# HT32F125x register map
File version: 1.1
CPU: CM3 r2p0, little endian, no MPU, no FPU, 4 interrupt priority bits
Registers are 32-bit, read-write, reset 0x0 unless marked. A register's access mark holds for its fields unless they carry their own. Offsets are from the block's base; [hi:lo] are bit positions; {n}, {i} and the like mark numbered series.

## FMC
Base 0x40080000
0x00 FMC_TADR
  [31:0] TADB
0x04 FMC_WRDR
  [31:0] WRDB
0x0C FMC_OCMR
  [3:0] CMD
0x10 FMC_OPCR
  [4:1] OPM
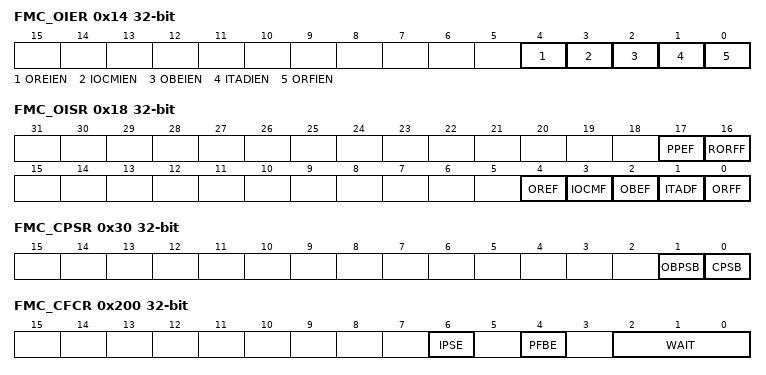
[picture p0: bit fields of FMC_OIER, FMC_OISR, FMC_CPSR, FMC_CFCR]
0x14 FMC_OIER
  [4] OREIEN, [3] IOCMIEN, [2] OBEIEN, [1] ITADIEN, [0] ORFIEN
0x18 FMC_OISR
  [17] PPEF, [16] RORFF, [4] OREF, [3] IOCMF, [2] OBEF, [1] ITADF, [0] ORFF
{0x20+4i} FMC_PPSR{i} (i=0..3)
  [31:0] PPSB
0x30 FMC_CPSR
  [1] OBPSB, [0] CPSB
0x100 FMC_VMCR
  [1:0] VMCB
0x200 FMC_CFCR
  [6] IPSE, [4] PFBE, [2:0] WAIT
{0x300+4i} FMC_SBVT{i} (i=0..3)
  [31:0] SBVT

## PWRCU
Base 0x4006A100
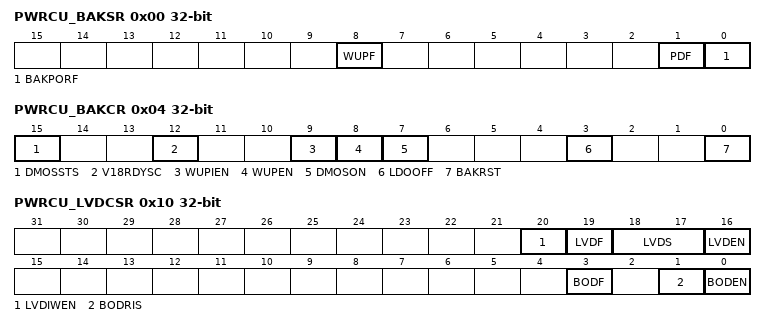
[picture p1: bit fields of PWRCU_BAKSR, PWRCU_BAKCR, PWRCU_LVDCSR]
0x00 PWRCU_BAKSR
  [8] WUPF, [1] PDF, [0] BAKPORF
0x04 PWRCU_BAKCR
  [15] DMOSSTS, [12] V18RDYSC, [9] WUPIEN, [8] WUPEN, [7] DMOSON, [3] LDOOFF, [0] BAKRST
0x08 PWRCU_BAKTEST
  [7:0] BAKTEST
0x0C PWRCU_HSIRCR
  [1:0] HSIRCBL
0x10 PWRCU_LVDCSR
  [20] LVDIWEN, [19] LVDF, [18:17] LVDS, [16] LVDEN, [3] BODF, [1] BODRIS, [0] BODEN
{0x100+4i} PWRCU_BAKREG{i} (i=0..9)
  [31:0] BAKREG

## CKCU
Base 0x40088000
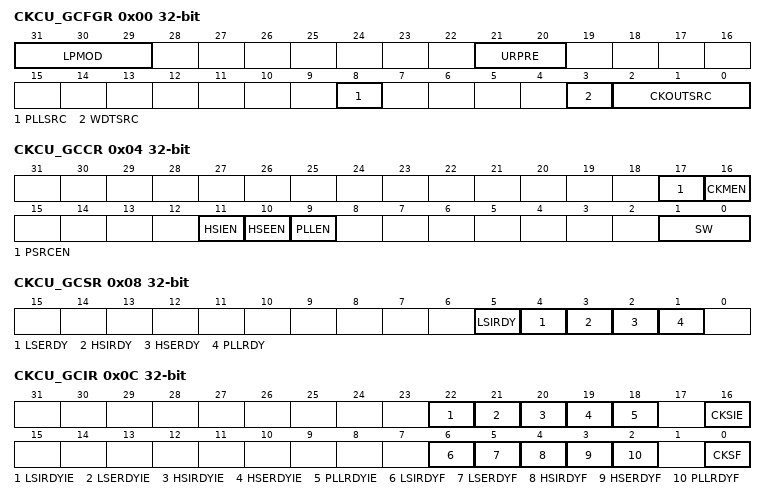
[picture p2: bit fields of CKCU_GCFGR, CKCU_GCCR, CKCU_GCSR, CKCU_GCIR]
0x00 CKCU_GCFGR
  [31:29] LPMOD, [21:20] URPRE, [8] PLLSRC, [3] WDTSRC, [2:0] CKOUTSRC
0x04 CKCU_GCCR
  [17] PSRCEN, [16] CKMEN, [11] HSIEN, [10] HSEEN, [9] PLLEN, [1:0] SW
0x08 CKCU_GCSR
  [5] LSIRDY, [4] LSERDY, [3] HSIRDY, [2] HSERDY, [1] PLLRDY
0x0C CKCU_GCIR
  [22] LSIRDYIE, [21] LSERDYIE, [20] HSIRDYIE, [19] HSERDYIE, [18] PLLRDYIE, [16] CKSIE, [6] LSIRDYF, [5] LSERDYF, [4] HSIRDYF, [3] HSERDYF, [2] PLLRDYF, [0] CKSF
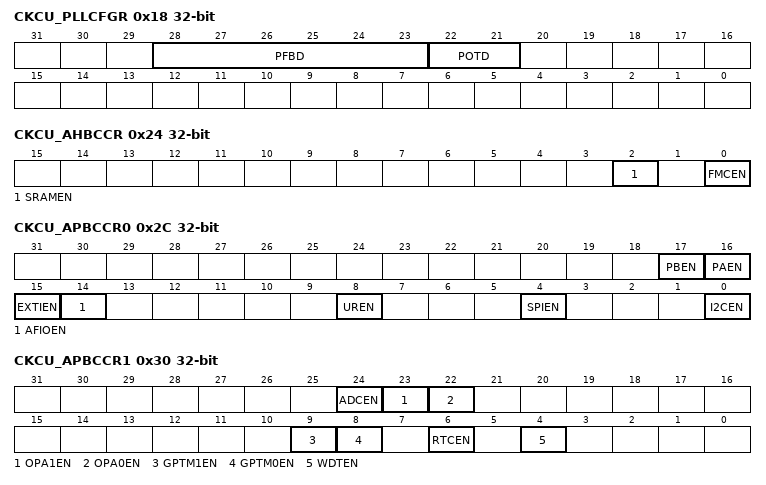
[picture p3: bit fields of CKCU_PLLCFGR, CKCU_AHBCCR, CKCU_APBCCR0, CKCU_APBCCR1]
0x18 CKCU_PLLCFGR
  [28:23] PFBD, [22:21] POTD
0x1C CKCU_PLLCR
  [31] PLLBPS
0x20 CKCU_AHBCFGR
  [1:0] AHBPRE
0x24 CKCU_AHBCCR
  [2] SRAMEN, [0] FMCEN
0x28 CKCU_APBCFGR
  [18:16] ADCDIV
0x2C CKCU_APBCCR0
  [17] PBEN, [16] PAEN, [15] EXTIEN, [14] AFIOEN, [8] UREN, [4] SPIEN, [0] I2CEN
0x30 CKCU_APBCCR1
  [24] ADCEN, [23] OPA1EN, [22] OPA0EN, [9] GPTM1EN, [8] GPTM0EN, [6] RTCEN, [4] WDTEN
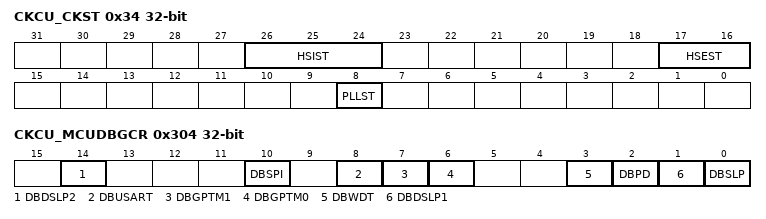
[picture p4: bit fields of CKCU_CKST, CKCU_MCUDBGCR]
0x34 CKCU_CKST
  [26:24] HSIST, [17:16] HSEST, [8] PLLST
0x300 CKCU_LPCR
  [0] BKISO
0x304 CKCU_MCUDBGCR
  [14] DBDSLP2, [10] DBSPI, [8] DBUSART, [7] DBGPTM1, [6] DBGPTM0, [3] DBWDT, [2] DBPD, [1] DBDSLP1, [0] DBSLP

## RSTCU
Base 0x40088100
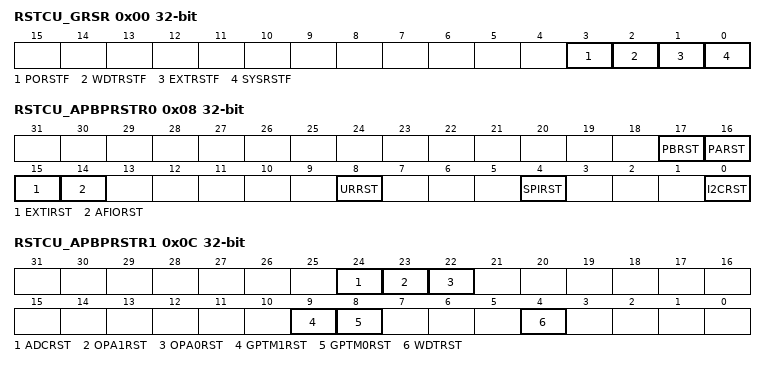
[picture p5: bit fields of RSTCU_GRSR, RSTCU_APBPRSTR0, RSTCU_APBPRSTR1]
0x00 RSTCU_GRSR
  [3] PORSTF, [2] WDTRSTF, [1] EXTRSTF, [0] SYSRSTF
0x08 RSTCU_APBPRSTR0
  [17] PBRST, [16] PARST, [15] EXTIRST, [14] AFIORST, [8] URRST, [4] SPIRST, [0] I2CRST
0x0C RSTCU_APBPRSTR1
  [24] ADCRST, [23] OPA1RST, [22] OPA0RST, [9] GPTM1RST, [8] GPTM0RST, [4] WDTRST

## GPIOA
Base 0x4001A000
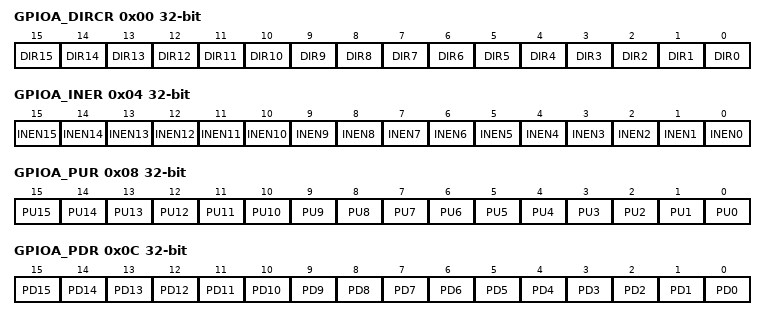
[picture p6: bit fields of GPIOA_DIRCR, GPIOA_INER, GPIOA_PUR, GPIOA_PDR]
0x00 GPIOA_DIRCR
  [n] DIR{n} (n=0..15)
0x04 GPIOA_INER
  [n] INEN{n} (n=0..15)
0x08 GPIOA_PUR
  [n] PU{n} (n=0..15)
0x0C GPIOA_PDR
  [n] PD{n} (n=0..15)
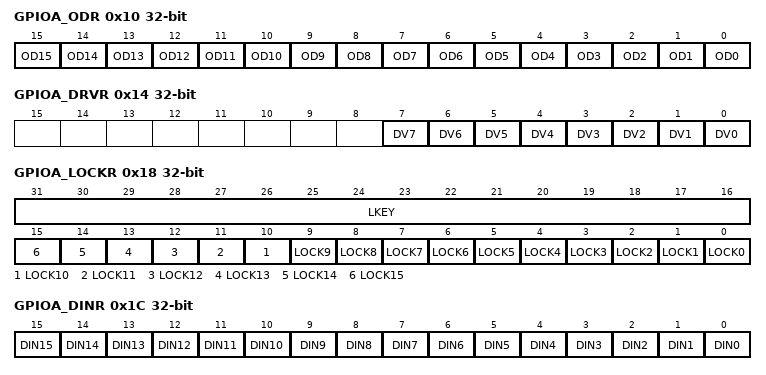
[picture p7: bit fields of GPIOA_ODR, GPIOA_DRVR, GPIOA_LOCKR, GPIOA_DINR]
0x10 GPIOA_ODR
  [n] OD{n} (n=0..15)
0x14 GPIOA_DRVR
  [n] DV{n} (n=0..7)
0x18 GPIOA_LOCKR
  [31:16] LKEY, [n] LOCK{n} (n=0..15)
0x1C GPIOA_DINR
  [n] DIN{n} (n=0..15)
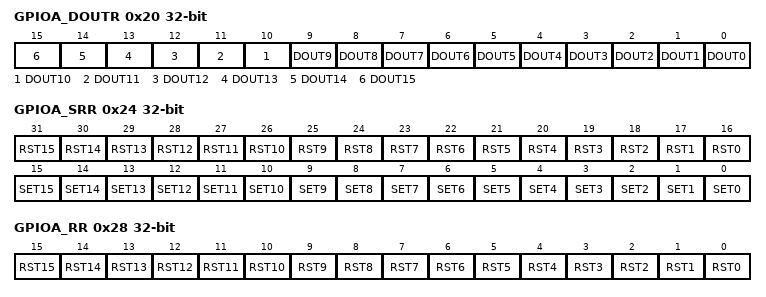
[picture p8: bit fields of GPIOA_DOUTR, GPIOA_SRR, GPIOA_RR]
0x20 GPIOA_DOUTR
  [n] DOUT{n} (n=0..15)
0x24 GPIOA_SRR
  [n+16] RST{n} (n=0..15), [n] SET{n} (n=0..15)
0x28 GPIOA_RR
  [n] RST{n} (n=0..15)

## GPIOB
Base 0x4001B000
Registers as GPIOA (with GPIOA read as GPIOB).

## AFIO
Base 0x40022000
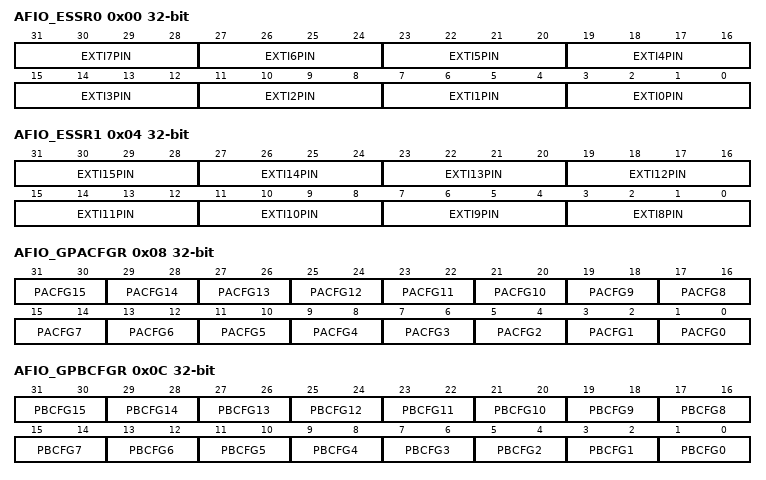
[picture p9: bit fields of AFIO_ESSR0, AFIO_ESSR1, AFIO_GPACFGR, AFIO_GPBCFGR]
0x00 AFIO_ESSR0
  [4n+3:4n] EXTI{n}PIN (n=0..7)
0x04 AFIO_ESSR1
  [4n-29:4n-32] EXTI{n}PIN (n=8..15)
0x08 AFIO_GPACFGR
  [2n+1:2n] PACFG{n} (n=0..15)
0x0C AFIO_GPBCFGR
  [2n+1:2n] PBCFG{n} (n=0..15)

## EXTI
Base 0x40024000
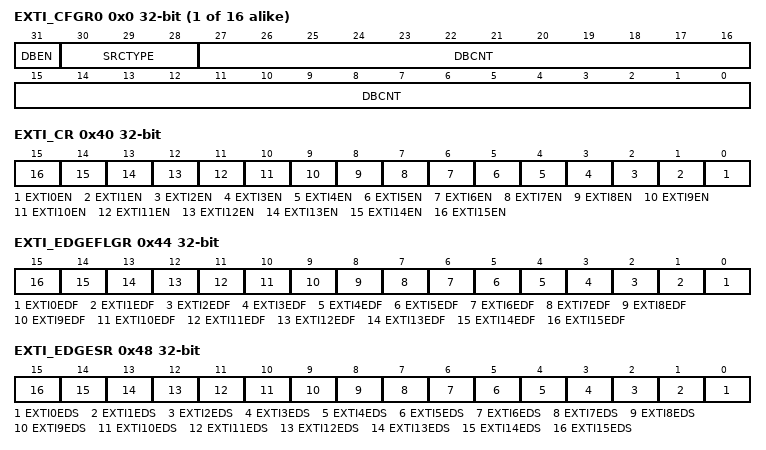
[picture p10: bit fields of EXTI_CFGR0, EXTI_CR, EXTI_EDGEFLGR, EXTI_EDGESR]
{0x0+4i} EXTI_CFGR{i} (i=0..15)
  [31] DBEN, [30:28] SRCTYPE, [27:0] DBCNT
0x40 EXTI_CR
  [n] EXTI{n}EN (n=0..15)
0x44 EXTI_EDGEFLGR
  [n] EXTI{n}EDF (n=0..15)
0x48 EXTI_EDGESR
  [n] EXTI{n}EDS (n=0..15)
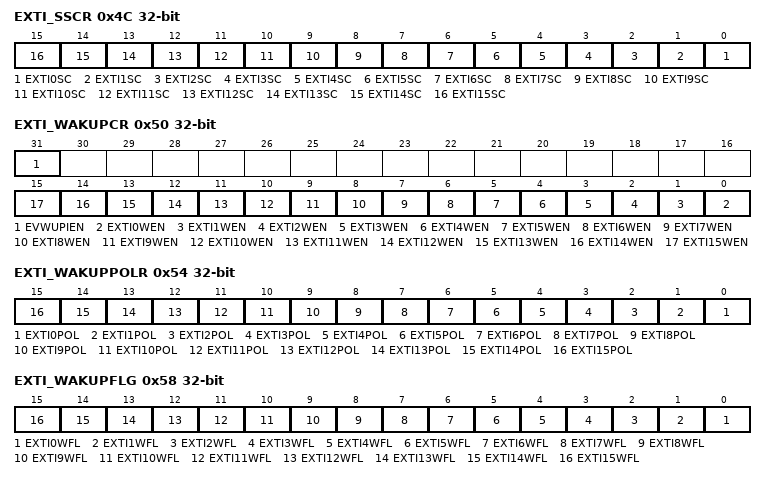
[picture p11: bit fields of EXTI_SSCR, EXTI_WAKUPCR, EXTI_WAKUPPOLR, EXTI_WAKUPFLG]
0x4C EXTI_SSCR
  [n] EXTI{n}SC (n=0..15)
0x50 EXTI_WAKUPCR
  [31] EVWUPIEN, [n] EXTI{n}WEN (n=0..15)
0x54 EXTI_WAKUPPOLR
  [n] EXTI{n}POL (n=0..15)
0x58 EXTI_WAKUPFLG
  [n] EXTI{n}WFL (n=0..15)

## ADC
Base 0x40010000
0x04 ADC_RST
  [0] ADRST
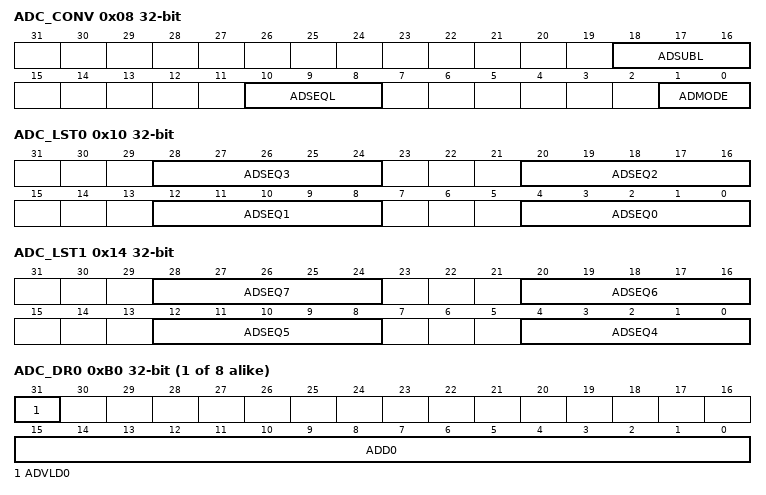
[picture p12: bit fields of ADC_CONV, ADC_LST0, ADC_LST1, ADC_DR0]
0x08 ADC_CONV
  [18:16] ADSUBL, [10:8] ADSEQL, [1:0] ADMODE
0x10 ADC_LST0
  [8n+4:8n] ADSEQ{n} (n=0..3)
0x14 ADC_LST1
  [8n-28:8n-32] ADSEQ{n} (n=4..7)
{0x70+4i} ADC_STR{i} (i=0..7)
  [7:0] ADST{i}
{0xB0+4i} ADC_DR{i} (i=0..7)
  [31] ADVLD{i}, [15:0] ADD{i}
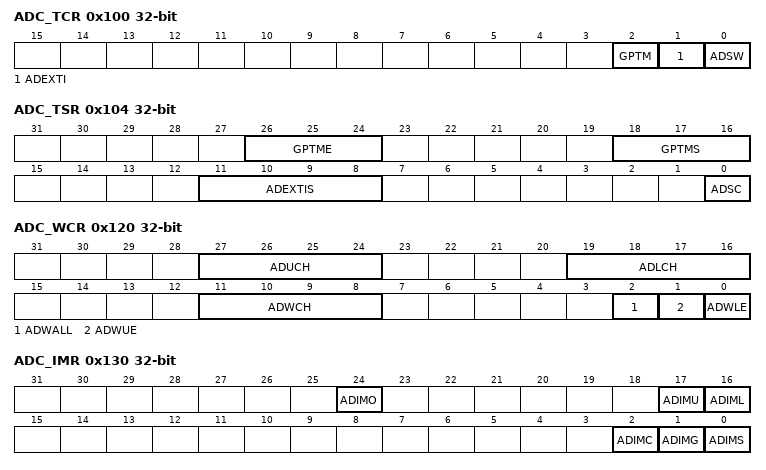
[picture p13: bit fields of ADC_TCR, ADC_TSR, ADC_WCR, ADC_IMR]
0x100 ADC_TCR
  [2] GPTM, [1] ADEXTI, [0] ADSW
0x104 ADC_TSR
  [26:24] GPTME, [18:16] GPTMS, [11:8] ADEXTIS, [0] ADSC
0x120 ADC_WCR
  [27:24] ADUCH, [19:16] ADLCH, [11:8] ADWCH, [2] ADWALL, [1] ADWUE, [0] ADWLE
0x124 ADC_LTR
  [11:0] ADLT
0x128 ADC_UTR
  [11:0] ADUT
0x130 ADC_IMR
  [24] ADIMO, [17] ADIMU, [16] ADIML, [2] ADIMC, [1] ADIMG, [0] ADIMS
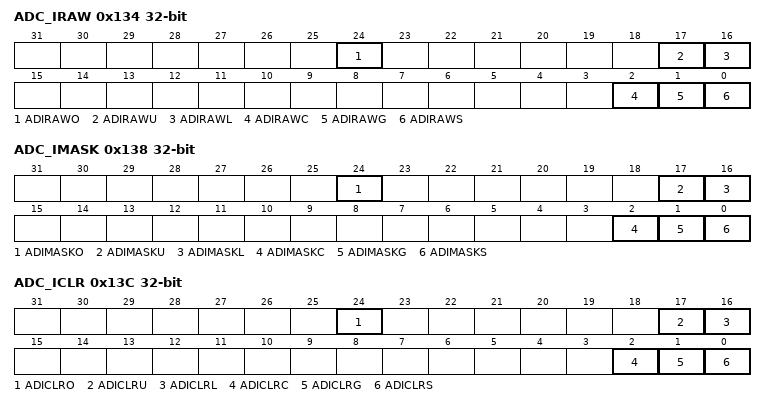
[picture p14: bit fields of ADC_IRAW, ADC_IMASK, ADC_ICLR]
0x134 ADC_IRAW
  [24] ADIRAWO, [17] ADIRAWU, [16] ADIRAWL, [2] ADIRAWC, [1] ADIRAWG, [0] ADIRAWS
0x138 ADC_IMASK
  [24] ADIMASKO, [17] ADIMASKU, [16] ADIMASKL, [2] ADIMASKC, [1] ADIMASKG, [0] ADIMASKS
0x13C ADC_ICLR
  [24] ADICLRO, [17] ADICLRU, [16] ADICLRL, [2] ADICLRC, [1] ADICLRG, [0] ADICLRS
